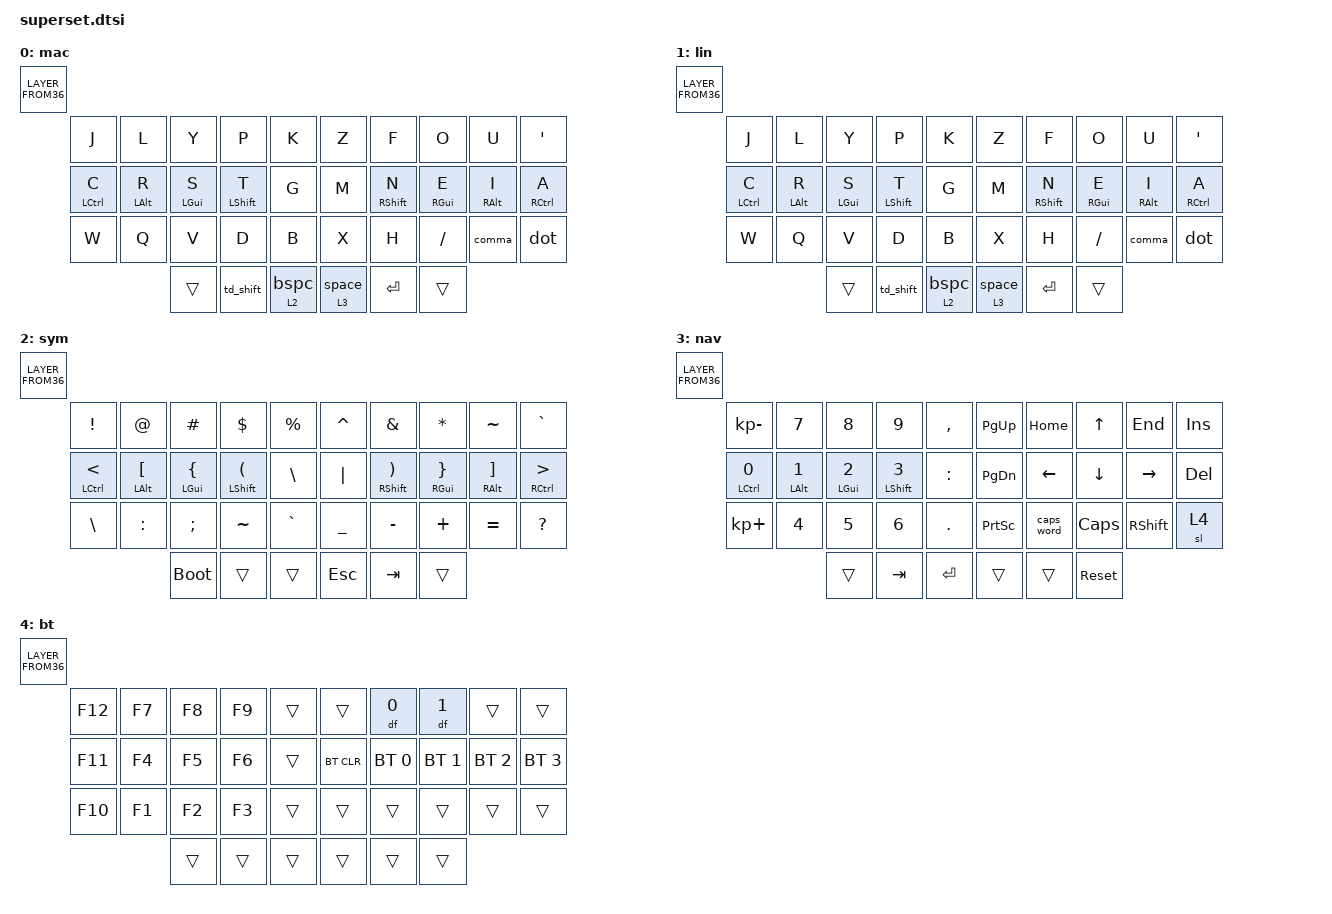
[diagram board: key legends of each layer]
/* #ifdef ENCODER */
/*   #define WRAPPED_ENCODER ENCODER "," */
/*   #ifndef ENCODER &none */
/* #endif */
/* #ifndef ENCODER */
/*   #define ENCODER "" */
/*   #define WRAPPED_ENCODER ENCODER */
/* #endif */

#ifndef EXTRA_BINDINGS
  #define EXTRA_BINDINGS ""
#endif


/*
 * Copyright (c) 2022 The ZMK Contributors
 *
 * SPDX-License-Identifier: MIT
 */

#include <behaviors.dtsi>
#include <dt-bindings/zmk/keys.h>
#include <dt-bindings/zmk/bt.h>
#include "elpekenin/behaviors.dtsi"

// TODO: remember to put this in the board keymap file
/* / { */
/*   chosen { */
/*     //zmk,matrix_transform = &default_transform; */
/*     zmk,matrix_transform = &five_column_transform; */
/*   }; */
/* }; */

/ {
    behaviors {
        shift: hold_tap_shift {
            compatible = "zmk,behavior-hold-tap";
            label = "HOLD_TAP_SHIFT";
            bindings = <&kp>, <&sk>;

            #binding-cells = <2>;
            tapping-term-ms = <150>;
            flavor = "tap-preferred";
        };

        td_shift: tap_dance_shift_caps_word {
            compatible = "zmk,behavior-tap-dance";
            label = "TAP_DANCE_SHIFT_CW";
            bindings = <&shift RSHIFT LSHIFT>, <&caps_word>;

            #binding-cells = <0>;
            tapping-term-ms = <200>;
        };

        hrm: homerow_mods {
            compatible = "zmk,behavior-hold-tap";
            label = "HOMEROW_MODS";
            bindings = <&kp>, <&kp>;

            #binding-cells = <2>;
            tapping-term-ms = <200>;
            require-prior-idle-ms = <125>;
            flavor = "tap-preferred";
        };

        hrs: homerow_shift {
            compatible = "zmk,behavior-hold-tap";
            label = "HOMEROW_SHIFT";
            bindings = <&kp>, <&kp>;

            #binding-cells = <2>;
            tapping-term-ms = <150>;
            flavor = "balanced";
        };

        lh: layer_hold {
          compatible = "zmk,behavior-hold-tap";
          label = "LAYER_HOLD";
          bindings = <&mo>, <&kp>;

          #binding-cells = <2>;
          tapping-term-ms = <200>;
          flavor = "hold-preferred";
        };

        bspc: bspc_del_on_shift {
            compatible = "zmk,behavior-mod-morph";
            label = "BSPC_DEL_ON_SHIFT";
            bindings = <&kp BSPC>, <&kp DEL>;

            #binding-cells = <0>;
            mods = <(MOD_LSFT|MOD_RSFT)>;
        };

        // the following only USES one argument but requires 2, so pass in the layer as the
        // first param and a dummy value like 0 as second
        lhbs: layer_hold_bspc_override {
            compatible = "zmk,behavior-hold-tap";
            label = "LAYER_HOLD_BSPC_OVERRIDE";
            bindings = <&mo>, <&bspc>;

            #binding-cells = <2>;
            tapping-term-ms = <200>;
        };

        space: space_tab_on_shift {
            compatible = "zmk,behavior-mod-morph";
            label = "SPACE_TAB_ON_SHIFT";
            bindings = <&kp SPACE>, <&kp TAB>;

            #binding-cells = <0>;
            mods = <(MOD_LSFT)>;
        };

        ltsp: layer_tap_space_override {
            compatible = "zmk,behavior-hold-tap";
            label = "LAYER_TAP_SPACE_OVERRIDE";
            bindings = <&mo>, <&space>;

            #binding-cells = <2>;
            tapping-term-ms = <200>;
            flavor = "tap-preferred";
        };

        comma: comma_semicolon_on_shift {
            compatible = "zmk,behavior-mod-morph";
            label = "COMMA_SEMICOLON_ON_SHIFT";
            bindings = <&kp COMMA>, <&kp SEMI>;

            #binding-cells = <0>;
            mods = <(MOD_LSFT)>;
        };

        dot: dot_colon_on_shift {
            compatible = "zmk,behavior-mod-morph";
            label = "DOT_COLON_ON_SHIFT";
            bindings = <&kp DOT>, <&kp COLON>;

            #binding-cells = <0>;
            mods = <(MOD_LSFT)>;
        };
    };

    combos {
        compatible = "zmk,combos";

        escape {
            bindings = <&kp ESC>;
            key-positions = <11 12>;
            require-prior-idle-ms = <40>;
            timeout-ms = <25>;
            // layers = <0 1>;
        };

        enter {
            bindings = <&kp ENTER>;
            key-positions = <17 18>;
            // key-positions = <27 28>;
            require-prior-idle-ms = <40>;
            timeout-ms = <20>;
        };

        tab {
            bindings = <&kp TAB>;
            key-positions = <12 13>;
            require-prior-idle-ms = <40>;
            timeout-ms = <20>;
        };

        caps {
            bindings = <&kp CAPS>;
            key-positions = <6 9>;
            require-prior-idle-ms = <40>;
            timeout-ms = <20>;
        };

        //*** OS specific combos ***//
        // mac combos
        copy {
            bindings = <&kp LG(C)>;
            key-positions = <22 21>;
            layers = <0>;
        };

        paste {
            bindings = <&kp LG(V)>;
            key-positions = <22 23>;
            layers = <0>;
        };

        cut {
            bindings = <&kp LG(X)>;
            key-positions = <21 23>;
            layers = <0>;
        };

        back_word {
            bindings = <&kp LA(BSPC)>;
            key-positions = <11 13>;
            require-prior-idle-ms = <50>;
            timeout-ms = <20>;
            layers = <0>;
        };

        del_word {
            bindings = <&kp LA(DEL)>;
            key-positions = <16 18>;
            require-prior-idle-ms = <50>;
            timeout-ms = <20>;
            layers = <0>;
        };

        undo {
            bindings = <&kp LG(Z)>;
            key-positions = <6 7>;
            require-prior-idle-ms = <50>;
            timeout-ms = <20>;
            layers = <0>;
        };

        redo {
            bindings = <&kp LG(LS(Z))>;
            key-positions = <7 8>;
            require-prior-idle-ms = <50>;
            timeout-ms = <20>;
            layers = <0>;
        };

        // linux combos
        copy_lin {
            bindings = <&kp LC(C)>;
            key-positions = <22 21>;
            layers = <1>;
        };

        paste_lin {
            bindings = <&kp LC(V)>;
            key-positions = <22 23>;
            layers = <1>;
        };

        cut_lin {
            bindings = <&kp LC(X)>;
            key-positions = <21 23>;
            layers = <1>;
        };

        back_word_lin {
            bindings = <&kp LC(BSPC)>;
            key-positions = <11 13>;
            require-prior-idle-ms = <50>;
            timeout-ms = <20>;
            layers = <1>;
        };

        del_word_lin {
            bindings = <&kp LC(DEL)>;
            key-positions = <16 18>;
            require-prior-idle-ms = <50>;
            timeout-ms = <20>;
            layers = <1>;
        };

        undo_lin {
            bindings = <&kp LC(Z)>;
            key-positions = <6 7>;
            require-prior-idle-ms = <50>;
            timeout-ms = <20>;
            layers = <1>;
        };

        redo_lin {
            bindings = <&kp LC(Y)>;
            key-positions = <7 8>;
            require-prior-idle-ms = <50>;
            timeout-ms = <20>;
            layers = <1>;
        };

    };

    keymap {
        compatible = "zmk,keymap";

        mac {
            label = "mac";
            //╭──────────┬──────────┬──────────┬──────────┬──────────╮     ╭──────────┬──────────┬──────────┬──────────┬──────────╮
            //│  Q       │  W       │  F       │  P       │  B       │     │  J       │  L       │  U       │  Y       │  '"      │
            //├──────────┼──────────┼──────────┼──────────┼──────────┤     ├──────────┼──────────┼──────────┼──────────┼──────────┤
            //│  A       │  R       │  S       │  T       │  G       │     │  M       │  N       │  E       │  I       │  O       │
            //├──────────┼──────────┼──────────┼──────────┼──────────┤     ├──────────┼──────────┼──────────┼──────────┼──────────┤
            //│  Z       │  X       │  C       │  D       │  V       │     │  K       │  H       │  , ;     │  . :     │  / ?     │
            //╰──────────┴──────────┴──────────┼──────────┼──────────┤     ├──────────┼──────────┼──────────┴──────────┴──────────╯
            //                      │          │          │          │     │          │          │          │
            //                      ╰──────────┴──────────┴──────────╯     ╰──────────┴──────────┴──────────╯
            bindings = <LAYER_FROM36( \
             &kp J,      &kp L,      &kp Y,      &kp P,      &kp K,                             &kp Z,      &kp F,      &kp O,      &kp U,      &kp SQT, \
        &hrm LCTRL C,  &hrm LALT R,  &hrm LGUI S,  &hrs LSHFT T,  &kp G,                     &kp M,   &hrs RSHFT N,  &hrm RGUI E,  &hrm RALT I,  &hrm RCTRL A, \
             &kp W,      &kp Q,      &kp V,      &kp D,      &kp B,                             &kp X,      &kp H,      &kp FSLH,   &comma,  &dot, \
                                   &trans,   &td_shift,      &lhbs 2 0,                          &ltsp 3 0,     &kp ENTER,      &trans
            )>;
        };

        linux {
            label = "lin";
            bindings = <LAYER_FROM36( \
             &kp J,      &kp L,      &kp Y,      &kp P,      &kp K,                             &kp Z,      &kp F,      &kp O,      &kp U,      &kp SQT, \
             &hrm LCTRL C,  &hrm LALT R,  &hrm LGUI S,  &hrs LSHFT T,  &kp G,                     &kp M,   &hrs RSHFT N,  &hrm RGUI E,  &hrm RALT I,  &hrm RCTRL A, \
             &kp W,      &kp Q,      &kp V,      &kp D,      &kp B,                             &kp X,      &kp H,      &kp FSLH,   &comma,  &dot, \
                                   &trans,   &td_shift,      &lhbs 2 0,                          &ltsp 3 0,     &kp ENTER,      &trans
            )>;
        };

        sym_layer {
            label = "sym";
        //╭──────────┬──────────┬──────────┬──────────┬──────────╮      ╭──────────┬──────────┬──────────┬──────────┬──────────╮
        //│  !       │  @       │   #      │    $     │     %    │      │  ^       │   &      │  *       │  ~       │  `       │
        //├──────────┼──────────┼──────────┼──────────┼──────────┤      ├──────────┼──────────┼──────────┼──────────┼──────────┤
        //│  <       │  [       │  {       │  (       │  \       │      │  |       │  )       │  }       │  ]       │  >       │
        //├──────────┼──────────┼──────────┼──────────┼──────────┤      ├──────────┼──────────┼──────────┼──────────┼──────────┤
        //│   \      │ ~        │ `~       │  "       │ '"       │      │  _       │   -      │  +       │  =       │  ?       │
        //╰──────────┴──────────┴──────────┼──────────┼──────────┤      ├──────────┼──────────┼──────────┴──────────┴──────────╯
        //                      │          │          │          │      │          │          │          │
        //                      ╰──────────┴──────────┴──────────╯      ╰──────────┴──────────┴──────────╯

            bindings = <LAYER_FROM36( \
              &kp EXCLAMATION,  &kp AT,     &kp HASH,   &kp DOLLAR,  &kp PERCENT,    &kp CARET,  &kp AMPS,   &kp STAR,   &kp TILDE,  &kp GRAVE, \
              &hrm LCTRL LESS_THAN,  &hrm LALT LBKT,  &hrm LGUI LBRC,  &hrs LSHFT LPAR,   &kp BSLH,  &kp PIPE,  &hrs RSHFT RPAR,  &hrm RGUI RBRC,  &hrm RALT RBKT,  &hrm RCTRL GREATER_THAN, \
              &kp BSLH,      &kp COLON,   &kp SEMI, &kp TILDE,  &kp GRAVE,         &kp UNDER,      &kp MINUS,    &kp PLUS,    &kp EQUAL,  &kp QMARK, \
                                      &bootloader,     &trans,      &trans,         &kp ESC,  &kp TAB,  &trans
            )>;
        };

        nav_layer {
        //╭──────────┬──────────┬──────────┬──────────┬──────────╮      ╭──────────┬──────────┬──────────┬──────────┬──────────╮
        //│    -     │     7    │     8    │     9    │    ,     │      │  PG UP   │  HOME    │    UP    │  END     │   INS    │
        //├──────────┼──────────┼──────────┼──────────┼──────────┤      ├──────────┼──────────┼──────────┼──────────┼──────────┤
        //│     0    │     1    │     2    │    3     │    :     │      │  PG DN   │  LEFT    │  DOWN    │  RIGHT   │  DEL     │
        //├──────────┼──────────┼──────────┼──────────┼──────────┤      ├──────────┼──────────┼──────────┼──────────┼──────────┤
        //│     +    │     4    │     5    │    6     │    .     │      │  PRINT   │CAPS WORD │  CAPS    │  SHIFT   │   SL 3   │
        //╰──────────┴──────────┴──────────┼──────────┼──────────┤      ├──────────┼──────────┼──────────┴──────────┴──────────╯
        //                      ╰──────────┴──────────┴──────────╯      ╰──────────┴──────────┴──────────╯
            label = "nav";
            bindings = <LAYER_FROM36( \
              &kp KP_MINUS,    &kp N7,      &kp N8,      &kp N9,   &kp COMMA,          &kp PG_UP,  &kp HOME,    &kp UP,     &kp END,   &kp INS, \
              &hrm LCTRL N0,   &hrm LALT N1,  &hrm LGUI N2,     &hrs LSHFT N3,     &kp COLON,           &kp PG_DN,  &kp LEFT,  &kp DOWN,    &kp RIGHT,   &kp DEL, \
              &kp KP_PLUS,  &kp N4,    &kp N5,      &kp N6,   &kp DOT,            &kp PSCRN, &caps_word,   &kp CAPS, &kp RSHFT,  &sl 4, \
                                    &trans,  &kp TAB,     &kp ENTER,         &trans,      &trans,   &sys_reset
            )>;
        };

        bt {
        // TODO: consider matching the numpad layer in this arrangement
        //╭──────────┬──────────┬──────────┬──────────┬──────────╮      ╭──────────┬──────────┬──────────┬──────────┬──────────╮
        //│    F12   │    F7    │    F8    │    F9    │          │      │          │    mac   │  linux   │          │          │
        //├──────────┼──────────┼──────────┼──────────┼──────────┤      ├──────────┼──────────┼──────────┼──────────┼──────────┤
        //│    F11   │    F4    │    F5    │    F6    │          │      │          │          │          │          │          │
        //├──────────┼──────────┼──────────┼──────────┼──────────┤      ├──────────┼──────────┼──────────┼──────────┼──────────┤
        //│    F10   │    F1    │    F2    │    F3    │          │      │          │          │          │          │          │
        //╰──────────┴──────────┴──────────┼──────────┼──────────┤      ├──────────┼──────────┼──────────┴──────────┴──────────╯
        //                      │          │          │          │      │          │          │          │
        //                      ╰──────────┴──────────┴──────────╯      ╰──────────┴──────────┴──────────╯
            display-name = "bt";
            bindings = <LAYER_FROM36( \
               &kp F12,    &kp F7,     &kp F8,     &kp F9,       &trans,            &trans,     &df 0,     &df 1,      &trans,     &trans, \
               &kp F11,    &kp F4,     &kp F5,     &kp F6,       &trans,         &bt BT_CLR, &bt BT_SEL 0, &bt BT_SEL 1, &bt BT_SEL 2, &bt BT_SEL 3, \
               &kp F10,    &kp F1,     &kp F2,     &kp F3,       &trans,            &trans,     &trans,     &trans,     &trans,     &trans, \
                                       &trans,     &trans,     &trans,            &trans,     &trans,     &trans
            )>;
        };
    };
};
